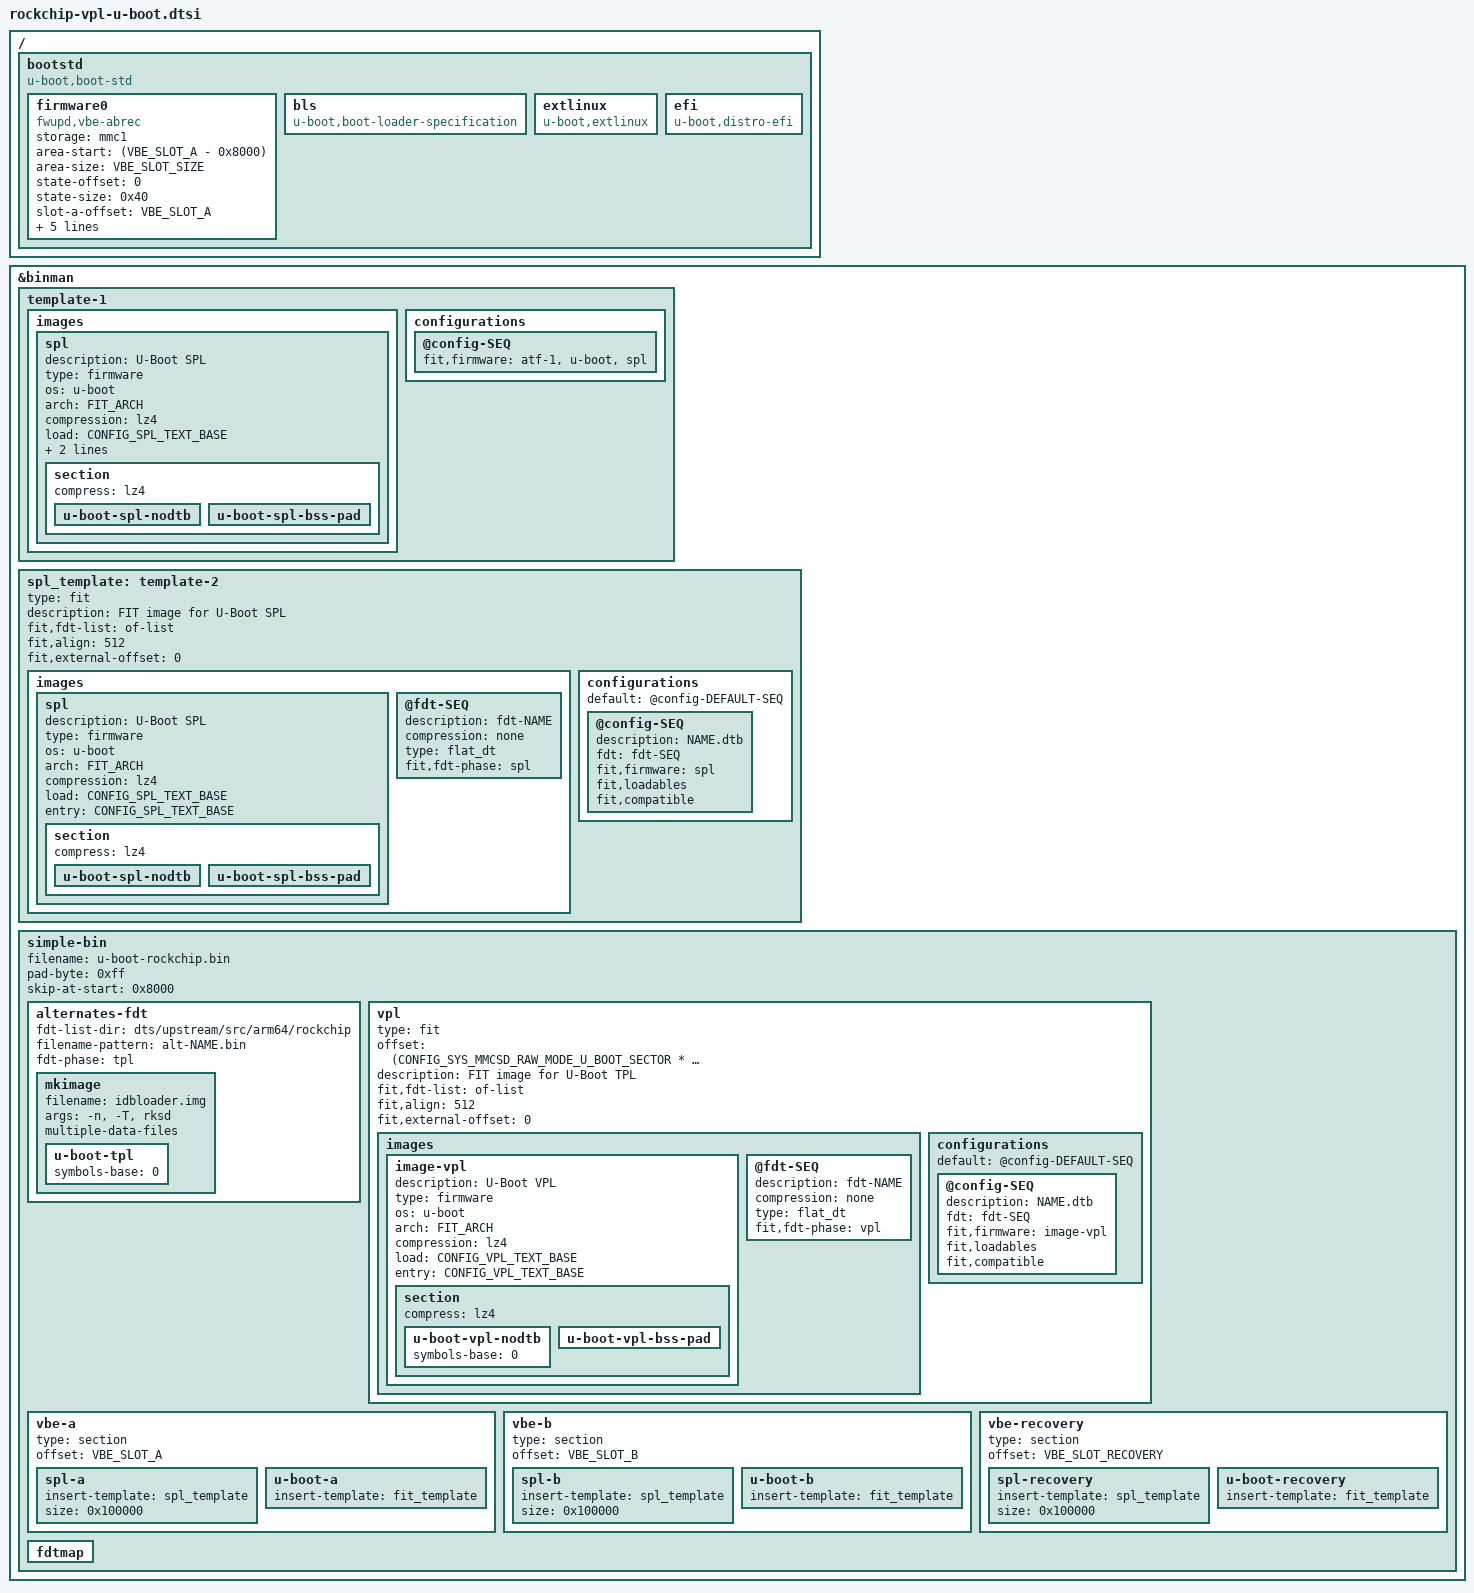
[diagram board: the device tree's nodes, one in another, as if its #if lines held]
// SPDX-License-Identifier: GPL-2.0+
/*
 * Copyright (C) 2019 Jagan Teki <jagan@amarulasolutions.com>
 */

/*
 * VBE abrec firmware slots: each holds an SPL FIT followed by a U-Boot FIT.
 * These are the offsets in the boot media, which match the binman offsets
 * since the image skips the first 32KB of the media
 */
#define VBE_SLOT_A		CONFIG_SPL_PAD_TO
#define VBE_SLOT_B		0x1000000
#define VBE_SLOT_RECOVERY	0x1800000
#define VBE_SLOT_SIZE		0x800000

/ {
	bootstd {
		bootph-verify;
		compatible = "u-boot,boot-std";

		/*
		 * This is used for the VBE OS-request tests. A FAT filesystem
		 * created in a partition with the VBE information appearing
		 * before the partition starts.
		 *
		 * Offsets are aligned to the media block-size, typically 0x200
		 *
		 * The VBE area starts 32KB below the A slot. It holds the state
		 * followed by a block containing the version information. These
		 * could be stored in a different storage device if available,
		 * but so far VBE only supports MMC. VPL reads them from the SD
		 * card (mmc1), the same media as the firmware.
		 *
		 * The slot properties tell an updater such as fwupd where the
		 * firmware lives: it writes new firmware to the B slot, which
		 * VPL tries, then copies it to A once it has booted
		 */
		firmware0 {
			bootph-verify;
			compatible = "fwupd,vbe-abrec";
			storage = "mmc1";
			area-start = <(VBE_SLOT_A - 0x8000)>;
			area-size = <VBE_SLOT_SIZE>;
			state-offset = <0>;
			state-size = <0x40>;
			slot-a-offset = <VBE_SLOT_A>;
			slot-b-offset = <VBE_SLOT_B>;
			slot-recovery-offset = <VBE_SLOT_RECOVERY>;
			slot-size = <VBE_SLOT_SIZE>;

			/* the updater describes the firmware at the end of each slot */
			slot-info-offset = <(VBE_SLOT_SIZE - 0x1000)>;
			slot-info-size = <0x1000>;
		};

		/*
		 * Declaring firmware0 above means dm_scan_other() finds a
		 * bootmeth in the devicetree and so does not bind the built-in
		 * list. Without these, a VBE board has no way to boot an OS,
		 * since a global bootmeth only loads firmware
		 */
		bls {
			compatible = "u-boot,boot-loader-specification";
		};

		extlinux {
			compatible = "u-boot,extlinux";
		};

		efi {
			compatible = "u-boot,distro-efi";
		};
	};
};

&binman {
	template-1 {
		images {
			spl {
				description = "U-Boot SPL";
				type = "firmware";
				os = "u-boot";
				arch = FIT_ARCH;
				compression = "lz4";
				load = <CONFIG_SPL_TEXT_BASE>;
				entry = <CONFIG_SPL_TEXT_BASE>;
				phase = "spl";
				section {
					compress = "lz4";
					u-boot-spl-nodtb {
					};
					u-boot-spl-bss-pad {
					};
				};
			};
		};
		configurations {
			@config-SEQ {
				fit,firmware = "atf-1", "u-boot", "spl";
			};
		};
	};

	spl_template: template-2 {
		type = "fit";
		description = "FIT image for U-Boot SPL";
		#address-cells = <1>;
		fit,fdt-list = "of-list";
		fit,align = <512>;
		fit,external-offset = <0>;
		images {
			spl {
				description = "U-Boot SPL";
				type = "firmware";
				os = "u-boot";
				arch = FIT_ARCH;
				compression = "lz4";
				load = <CONFIG_SPL_TEXT_BASE>;
				entry = <CONFIG_SPL_TEXT_BASE>;
				section {
					compress = "lz4";
					u-boot-spl-nodtb {
					};
					u-boot-spl-bss-pad {
					};
				};
			};
			@fdt-SEQ {
				description = "fdt-NAME";
				compression = "none";
				type = "flat_dt";
				fit,fdt-phase = "spl";
			};
		};
		configurations {
			default = "@config-DEFAULT-SEQ";
			@config-SEQ {
				description = "NAME.dtb";
				fdt = "fdt-SEQ";
				fit,firmware = "spl";
				fit,loadables;
				fit,compatible;
			};
		};
	};

	simple-bin {
		filename = "u-boot-rockchip.bin";
		pad-byte = <0xff>;
		skip-at-start = <0x8000>;

		alternates-fdt {
			fdt-list-dir = "dts/upstream/src/arm64/rockchip";
			filename-pattern = "alt-NAME.bin";
			fdt-phase = "tpl";

			mkimage {
				filename = "idbloader.img";
				args = "-n", CONFIG_SYS_SOC, "-T", "rksd";
				multiple-data-files;

				u-boot-tpl {
					symbols-base = <0>;
				};
			};
		};

		vpl {
			type = "fit";
			offset = <(CONFIG_SYS_MMCSD_RAW_MODE_U_BOOT_SECTOR * 0x200)>;
			description = "FIT image for U-Boot TPL";
			#address-cells = <1>;
			fit,fdt-list = "of-list";
			fit,align = <512>;
			fit,external-offset = <0>;
			images {
				image-vpl {
					description = "U-Boot VPL";
					type = "firmware";
					os = "u-boot";
					arch = FIT_ARCH;
					compression = "lz4";
					load = <CONFIG_VPL_TEXT_BASE>;
					entry = <CONFIG_VPL_TEXT_BASE>;
					section {
						compress = "lz4";
						u-boot-vpl-nodtb {
							symbols-base = <0>;
						};
						u-boot-vpl-bss-pad {
						};
					};
				};
				@fdt-SEQ {
					description = "fdt-NAME";
					compression = "none";
					type = "flat_dt";
					fit,fdt-phase = "vpl";
				};
			};
			configurations {
				default = "@config-DEFAULT-SEQ";
				@config-SEQ {
					description = "NAME.dtb";
					fdt = "fdt-SEQ";
					fit,firmware = "image-vpl";
					fit,loadables;
					fit,compatible;
				};
			};
		};
# ifdef CONFIG_BOOTMETH_VBE_ABREC
		vbe-a {
			type = "section";
			offset = <VBE_SLOT_A>;
			spl-a {
				insert-template = <&spl_template>;
				size = <0x100000>;
			};

			u-boot-a {
				insert-template = <&fit_template>;
			};
		};
		vbe-b {
			type = "section";
			offset = <VBE_SLOT_B>;
			spl-b {
				insert-template = <&spl_template>;
				size = <0x100000>;
			};

			u-boot-b {
				insert-template = <&fit_template>;
			};
		};
		vbe-recovery {
			type = "section";
			offset = <VBE_SLOT_RECOVERY>;
			spl-recovery {
				insert-template = <&spl_template>;
				size = <0x100000>;
			};

			u-boot-recovery {
				insert-template = <&fit_template>;
			};
		};
# else /* CONFIG_BOOTMETH_VBE_SIMPLE */
		vbe {
			type = "fit";
			offset = <CONFIG_SPL_PAD_TO>;
			insert-template = <&fit_template>;
		};
# endif /* VBE method */
		fdtmap {
		};
	};
};
